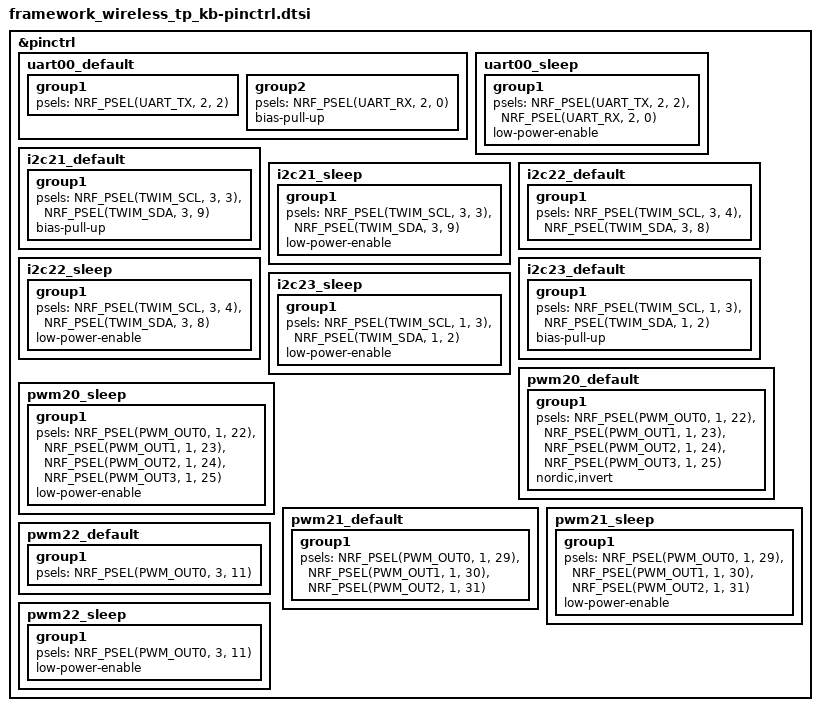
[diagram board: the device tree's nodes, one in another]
/*
 * Copyright (c) 2026 Framework Computer Inc
 * SPDX-License-Identifier: Apache-2.0
 */

&pinctrl {
	uart00_default: uart00_default {
		group1 {
			psels = <NRF_PSEL(UART_TX, 2, 2)>;
		};

		group2 {
			psels = <NRF_PSEL(UART_RX, 2, 0)>;
			bias-pull-up;
		};
	};

	uart00_sleep: uart00_sleep {
		group1 {
			psels = <NRF_PSEL(UART_TX, 2, 2)>,
				<NRF_PSEL(UART_RX, 2, 0)>;
			low-power-enable;
		};
	};

	/* nPM1300 PMIC */
	i2c21_default: i2c21_default {
		group1 {
			psels = <NRF_PSEL(TWIM_SCL, 3, 3)>,
				<NRF_PSEL(TWIM_SDA, 3, 9)>;
			bias-pull-up;
		};
	};

	i2c21_sleep: i2c21_sleep {
		group1 {
			psels = <NRF_PSEL(TWIM_SCL, 3, 3)>,
				<NRF_PSEL(TWIM_SDA, 3, 9)>;
			low-power-enable;
		};
	};

	/* Touchpad connector, external pull-ups */
	i2c22_default: i2c22_default {
		group1 {
			psels = <NRF_PSEL(TWIM_SCL, 3, 4)>,
				<NRF_PSEL(TWIM_SDA, 3, 8)>;
		};
	};

	i2c22_sleep: i2c22_sleep {
		group1 {
			psels = <NRF_PSEL(TWIM_SCL, 3, 4)>,
				<NRF_PSEL(TWIM_SDA, 3, 8)>;
			low-power-enable;
		};
	};

	/* Pin header */
	i2c23_default: i2c23_default {
		group1 {
			psels = <NRF_PSEL(TWIM_SCL, 1, 3)>,
				<NRF_PSEL(TWIM_SDA, 1, 2)>;
			bias-pull-up;
		};
	};

	i2c23_sleep: i2c23_sleep {
		group1 {
			psels = <NRF_PSEL(TWIM_SCL, 1, 3)>,
				<NRF_PSEL(TWIM_SDA, 1, 2)>;
			low-power-enable;
		};
	};

	/* White pairing LEDs, active low */
	pwm20_default: pwm20_default {
		group1 {
			psels = <NRF_PSEL(PWM_OUT0, 1, 22)>,
				<NRF_PSEL(PWM_OUT1, 1, 23)>,
				<NRF_PSEL(PWM_OUT2, 1, 24)>,
				<NRF_PSEL(PWM_OUT3, 1, 25)>;
			nordic,invert;
		};
	};

	pwm20_sleep: pwm20_sleep {
		group1 {
			psels = <NRF_PSEL(PWM_OUT0, 1, 22)>,
				<NRF_PSEL(PWM_OUT1, 1, 23)>,
				<NRF_PSEL(PWM_OUT2, 1, 24)>,
				<NRF_PSEL(PWM_OUT3, 1, 25)>;
			low-power-enable;
		};
	};

	/* RGB status LED */
	pwm21_default: pwm21_default {
		group1 {
			psels = <NRF_PSEL(PWM_OUT0, 1, 29)>,
				<NRF_PSEL(PWM_OUT1, 1, 30)>,
				<NRF_PSEL(PWM_OUT2, 1, 31)>;
		};
	};

	pwm21_sleep: pwm21_sleep {
		group1 {
			psels = <NRF_PSEL(PWM_OUT0, 1, 29)>,
				<NRF_PSEL(PWM_OUT1, 1, 30)>,
				<NRF_PSEL(PWM_OUT2, 1, 31)>;
			low-power-enable;
		};
	};

	/* Keyboard backlight */
	pwm22_default: pwm22_default {
		group1 {
			psels = <NRF_PSEL(PWM_OUT0, 3, 11)>;
		};
	};

	pwm22_sleep: pwm22_sleep {
		group1 {
			psels = <NRF_PSEL(PWM_OUT0, 3, 11)>;
			low-power-enable;
		};
	};
};
